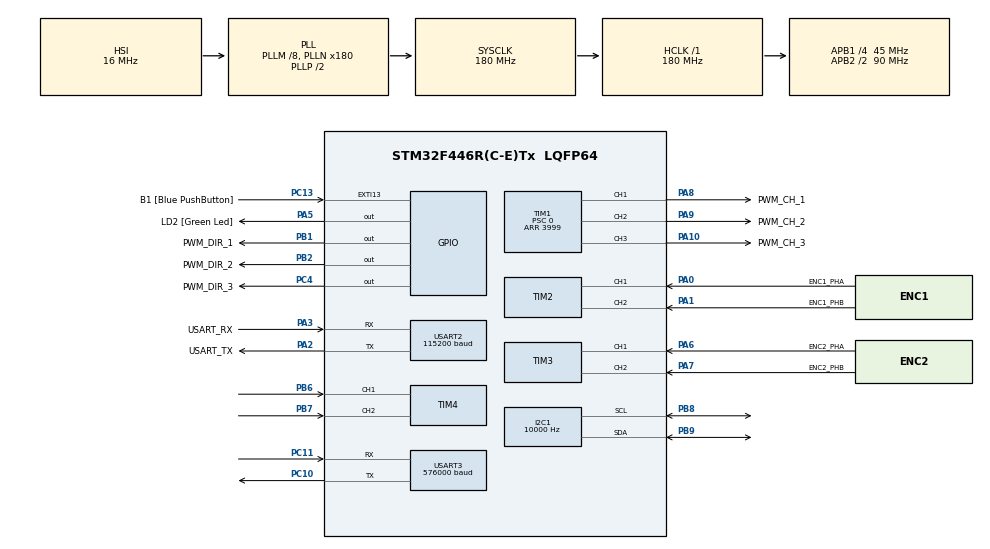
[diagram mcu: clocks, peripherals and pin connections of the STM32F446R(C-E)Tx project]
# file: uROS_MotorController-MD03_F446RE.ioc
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Dma.Request0=USART2_RX
Dma.Request1=USART2_TX
Dma.USART2_RX.0.Direction=DMA_PERIPH_TO_MEMORY
Dma.USART2_RX.0.FIFOMode=DMA_FIFOMODE_DISABLE
Dma.USART2_RX.0.Instance=DMA1_Stream5
Dma.USART2_RX.0.MemDataAlignment=DMA_MDATAALIGN_BYTE
Dma.USART2_RX.0.MemInc=DMA_MINC_ENABLE
Dma.USART2_RX.0.Mode=DMA_NORMAL
Dma.USART2_RX.0.PeriphDataAlignment=DMA_PDATAALIGN_BYTE
Dma.USART2_RX.0.PeriphInc=DMA_PINC_DISABLE
Dma.USART2_RX.0.Priority=DMA_PRIORITY_LOW
Dma.USART2_TX.1.Direction=DMA_MEMORY_TO_PERIPH
Dma.USART2_TX.1.FIFOMode=DMA_FIFOMODE_DISABLE
Dma.USART2_TX.1.Instance=DMA1_Stream6
Dma.USART2_TX.1.MemDataAlignment=DMA_MDATAALIGN_BYTE
Dma.USART2_TX.1.MemInc=DMA_MINC_ENABLE
Dma.USART2_TX.1.Mode=DMA_NORMAL
Dma.USART2_TX.1.PeriphDataAlignment=DMA_PDATAALIGN_BYTE
Dma.USART2_TX.1.PeriphInc=DMA_PINC_DISABLE
Dma.USART2_TX.1.Priority=DMA_PRIORITY_LOW
FREERTOS.Tasks01=defaultTask,24,128,StartDefaultTask,Default,NULL,Dynamic,NULL,NULL
FREERTOS.configTOTAL_HEAP_SIZE=0x5FFF
FREERTOS.configUSE_NEWLIB_REENTRANT=1
FREERTOS.configUSE_POSIX_ERRNO=1
FREERTOS.copyHeapFile=0
I2C1.ClockSpeed=10000
Mcu.Family=STM32F4
Mcu.Name=STM32F446R(C-E)Tx
Mcu.Package=LQFP64
NVIC.DMA1_Stream5_IRQn=true\:5\:0\:false\:false\:true\:true\:false\:true\:true
NVIC.DMA1_Stream6_IRQn=true\:5\:0\:false\:false\:true\:true\:false\:true\:true
NVIC.PriorityGroup=NVIC_PRIORITYGROUP_4
NVIC.TIM2_IRQn=true\:5\:0\:false\:false\:true\:true\:true\:true\:true
NVIC.TIM3_IRQn=true\:5\:0\:false\:false\:true\:true\:true\:true\:true
NVIC.TIM4_IRQn=true\:5\:0\:false\:false\:true\:true\:true\:true\:true
NVIC.TIM6_DAC_IRQn=true\:15\:0\:false\:false\:true\:false\:false\:true\:true
NVIC.TimeBase=TIM6_DAC_IRQn
NVIC.TimeBaseIP=TIM6
NVIC.USART2_IRQn=true\:5\:0\:false\:false\:true\:true\:true\:true\:true
NVIC.USART3_IRQn=true\:5\:0\:false\:false\:true\:true\:true\:true\:true
PA0-WKUP.GPIO_Label=ENC1_PHA
PA0-WKUP.GPIO_PuPd=GPIO_PULLUP
PA0-WKUP.Signal=S_TIM2_CH1_ETR
PA1.GPIO_Label=ENC1_PHB
PA1.GPIO_PuPd=GPIO_PULLUP
PA1.Signal=S_TIM2_CH2
PA10.GPIO_Label=PWM_CH_3
PA10.Signal=S_TIM1_CH3
PA13.GPIO_Label=TMS
PA13.Mode=Serial_Wire
PA13.Signal=SYS_JTMS-SWDIO
PA14.GPIO_Label=TCK
PA14.Mode=Serial_Wire
PA14.Signal=SYS_JTCK-SWCLK
PA2.GPIO_Label=USART_TX
PA2.Mode=Asynchronous
PA2.Signal=USART2_TX
PA3.GPIO_Label=USART_RX
PA3.Mode=Asynchronous
PA3.Signal=USART2_RX
PA5.GPIO_Label=LD2 [Green Led]
PA5.Signal=GPIO_Output
PA6.GPIO_Label=ENC2_PHA
PA6.GPIO_PuPd=GPIO_PULLUP
PA6.Signal=S_TIM3_CH1
PA7.GPIO_Label=ENC2_PHB
PA7.GPIO_PuPd=GPIO_PULLUP
PA7.Signal=S_TIM3_CH2
PA8.GPIO_Label=PWM_CH_1
PA8.Signal=S_TIM1_CH1
PA9.GPIO_Label=PWM_CH_2
PA9.Signal=S_TIM1_CH2
PB1.GPIO_Label=PWM_DIR_1
PB1.Signal=GPIO_Output
PB2.GPIO_Label=PWM_DIR_2
PB2.Signal=GPIO_Output
PB3.GPIO_Label=SWO
PB3.Signal=SYS_JTDO-SWO
PB6.Signal=S_TIM4_CH1
PB7.Signal=S_TIM4_CH2
PB8.GPIO_Pu=GPIO_PULLUP
PB8.Mode=I2C
PB8.Signal=I2C1_SCL
PB9.GPIO_Pu=GPIO_PULLUP
PB9.Mode=I2C
PB9.Signal=I2C1_SDA
PC10.Mode=Asynchronous
PC10.Signal=USART3_TX
PC11.Mode=Asynchronous
PC11.Signal=USART3_RX
PC13.GPIO_Label=B1 [Blue PushButton]
PC13.GPIO_ModeDefaultEXTI=GPIO_MODE_IT_FALLING
PC13.Signal=GPXTI13
PC14-OSC32_IN.Mode=LSE-External-Oscillator
PC14-OSC32_IN.Signal=RCC_OSC32_IN
PC15-OSC32_OUT.Mode=LSE-External-Oscillator
PC15-OSC32_OUT.Signal=RCC_OSC32_OUT
PC4.GPIO_Label=PWM_DIR_3
PC4.Signal=GPIO_Output
PH0-OSC_IN.Mode=HSE-External-Oscillator
PH0-OSC_IN.Signal=RCC_OSC_IN
PH1-OSC_OUT.Mode=HSE-External-Oscillator
PH1-OSC_OUT.Signal=RCC_OSC_OUT
ProjectManager.HeapSize=0x200
ProjectManager.StackSize=0x400
ProjectManager.TargetToolchain=STM32CubeIDE
RCC.48MHZClocksFreq_Value=84000000
RCC.AHBFreq_Value=180000000
RCC.APB1CLKDivider=RCC_HCLK_DIV4
RCC.APB1Freq_Value=45000000
RCC.APB1TimFreq_Value=90000000
RCC.APB2CLKDivider=RCC_HCLK_DIV2
RCC.APB2Freq_Value=90000000
RCC.APB2TimFreq_Value=180000000
RCC.CortexFreq_Value=180000000
RCC.FLatency-AdvancedSettings=FLASH_LATENCY_5
RCC.HCLKFreq_Value=180000000
RCC.HSE_VALUE=8000000
RCC.HSI_VALUE=16000000
RCC.PLLM=8
RCC.PLLN=180
RCC.SYSCLKFreq_VALUE=180000000
RCC.SYSCLKSource=RCC_SYSCLKSOURCE_PLLCLK
RCC.USBFreq_Value=180000000
RCC.VCOOutputFreq_Value=360000000
SH.S_TIM1_CH1.0=TIM1_CH1,PWM Generation1 CH1
SH.S_TIM1_CH2.0=TIM1_CH2,PWM Generation2 CH2
SH.S_TIM1_CH3.0=TIM1_CH3,PWM Generation3 CH3
SH.S_TIM2_CH1_ETR.0=TIM2_CH1,Encoder_Interface
SH.S_TIM2_CH2.0=TIM2_CH2,Encoder_Interface
SH.S_TIM3_CH1.0=TIM3_CH1,Encoder_Interface
SH.S_TIM3_CH2.0=TIM3_CH2,Encoder_Interface
SH.S_TIM4_CH1.0=TIM4_CH1,Encoder_Interface
SH.S_TIM4_CH2.0=TIM4_CH2,Encoder_Interface
TIM1.Channel-PWM\ Generation1\ CH1=TIM_CHANNEL_1
TIM1.Channel-PWM\ Generation2\ CH2=TIM_CHANNEL_2
TIM1.Channel-PWM\ Generation3\ CH3=TIM_CHANNEL_3
TIM1.Period=3999
TIM1.Prescaler=0
TIM2.EncoderMode=TIM_ENCODERMODE_TI12
TIM3.EncoderMode=TIM_ENCODERMODE_TI12
TIM4.EncoderMode=TIM_ENCODERMODE_TI12
USART2.BaudRate=115200
USART2.VirtualMode=VM_ASYNC
USART3.BaudRate=576000
USART3.VirtualMode=VM_ASYNC
VP_FREERTOS_VS_CMSIS_V2.Mode=CMSIS_V2
VP_SYS_VS_tim6.Mode=TIM6
VP_TIM1_VS_ClockSourceINT.Mode=Internal
board=NUCLEO-F446RE

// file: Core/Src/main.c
/* USER CODE BEGIN Header */
/**
  ******************************************************************************
  * @file           : main.c
  * @brief          : Main program body
  ******************************************************************************
  * @attention
  *
  * Copyright (c) 2022 STMicroelectronics.
  * All rights reserved.
  *
  * This software is licensed under terms that can be found in the LICENSE file
  * in the root directory of this software component.
  * If no LICENSE file comes with this software, it is provided AS-IS.
  *
  ******************************************************************************
  */
/* USER CODE END Header */
#include "main.h"
#include "cmsis_os.h"
#include "dma.h"
#include "i2c.h"
#include "tim.h"
#include "usart.h"
#include "gpio.h"

/* USER CODE BEGIN Includes */
#include "nomad_motor_task.h"
/* USER CODE END Includes */

void SystemClock_Config(void);
void MX_FREERTOS_Init(void);

int main(void)
{

  /* MCU Configuration--------------------------------------------------------*/

  /* Reset of all peripherals, Initializes the Flash interface and the Systick. */
  HAL_Init();

  /* Configure the system clock */
  SystemClock_Config();

  /* Initialize all configured peripherals */
  MX_GPIO_Init();
  MX_DMA_Init();
  MX_USART2_UART_Init();
  MX_I2C1_Init();
  MX_TIM1_Init();
  MX_TIM2_Init();
  MX_TIM3_Init();
  MX_TIM4_Init();
  MX_USART3_UART_Init();
  /* USER CODE BEGIN 2 */

  UROS_MOTOR_init();

  /* USER CODE END 2 */

  /* Init scheduler */
  osKernelInitialize();  /* Call init function for freertos objects (in freertos.c) */
  MX_FREERTOS_Init();

  /* Start scheduler */
  osKernelStart();

  /* We should never get here as control is now taken by the scheduler */
  /* Infinite loop */
  while (1)
  {

  }
}

void SystemClock_Config(void)
{
  RCC_OscInitTypeDef RCC_OscInitStruct = {0};
  RCC_ClkInitTypeDef RCC_ClkInitStruct = {0};

  /** Configure the main internal regulator output voltage
  */
  __HAL_RCC_PWR_CLK_ENABLE();
  __HAL_PWR_VOLTAGESCALING_CONFIG(PWR_REGULATOR_VOLTAGE_SCALE1);

  /** Initializes the RCC Oscillators according to the specified parameters
  * in the RCC_OscInitTypeDef structure.
  */
  RCC_OscInitStruct.OscillatorType = RCC_OSCILLATORTYPE_HSI;
  RCC_OscInitStruct.HSIState = RCC_HSI_ON;
  RCC_OscInitStruct.HSICalibrationValue = RCC_HSICALIBRATION_DEFAULT;
  RCC_OscInitStruct.PLL.PLLState = RCC_PLL_ON;
  RCC_OscInitStruct.PLL.PLLSource = RCC_PLLSOURCE_HSI;
  RCC_OscInitStruct.PLL.PLLM = 8;
  RCC_OscInitStruct.PLL.PLLN = 180;
  RCC_OscInitStruct.PLL.PLLP = RCC_PLLP_DIV2;
  RCC_OscInitStruct.PLL.PLLQ = 2;
  RCC_OscInitStruct.PLL.PLLR = 2;
  if (HAL_RCC_OscConfig(&RCC_OscInitStruct) != HAL_OK)
  {
    Error_Handler();
  }

  /** Activate the Over-Drive mode
  */
  if (HAL_PWREx_EnableOverDrive() != HAL_OK)
  {
    Error_Handler();
  }

  /** Initializes the CPU, AHB and APB buses clocks
  */
  RCC_ClkInitStruct.ClockType = RCC_CLOCKTYPE_HCLK|RCC_CLOCKTYPE_SYSCLK
                              |RCC_CLOCKTYPE_PCLK1|RCC_CLOCKTYPE_PCLK2;
  RCC_ClkInitStruct.SYSCLKSource = RCC_SYSCLKSOURCE_PLLCLK;
  RCC_ClkInitStruct.AHBCLKDivider = RCC_SYSCLK_DIV1;
  RCC_ClkInitStruct.APB1CLKDivider = RCC_HCLK_DIV4;
  RCC_ClkInitStruct.APB2CLKDivider = RCC_HCLK_DIV2;

  if (HAL_RCC_ClockConfig(&RCC_ClkInitStruct, FLASH_LATENCY_5) != HAL_OK)
  {
    Error_Handler();
  }
}

void HAL_TIM_PeriodElapsedCallback(TIM_HandleTypeDef *htim)
{
  if (htim->Instance == TIM6) {
    HAL_IncTick();
  }
}

void Error_Handler(void)
{
  __disable_irq();
  while (1)
  {
  }
}
